# V32F20x_CM33 register map
File version: 1.0.3
CPU: CM33 r0p4, little endian, MPU, FPU, DSP, 3 interrupt priority bits, 8 SAU regions
Registers are 32-bit, read-write, reset 0x0 unless marked. A register's access mark holds for its fields unless they carry their own. Offsets are from the block's base; [hi:lo] are bit positions; {n}, {i} and the like mark numbered series; <NAME> marks a mode.

## SPI0 — SPI0 Peripheral Interface
Base 0x40010000; alternate view of UART0
Same registers: SPI{n} {0x40010000+0x800*n} (alternate view of UART{n}) (n=1..13), SEC_SPI{n} {0x50010000+0x800*n} (alternate view of SEC_UART{n}) (n=0..13)
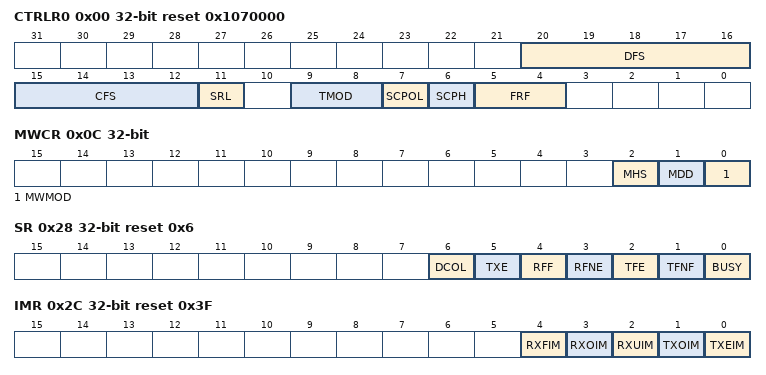
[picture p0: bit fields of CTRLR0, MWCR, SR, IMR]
0x00 CTRLR0 reset 0x1070000 — SPI Control Register 0.
  [20:16] DFS — Data Frame Size in 32-bit transfer size mode.
  [15:12] CFS — Control Frame Size.
  [11] SRL — Shift Register Loop
  [9:8] TMOD — Transfer Mode
  [7] SCPOL — Serial Clock Polarity.
  [6] SCPH — Serial Clock Phase
  [5:4] FRF — Frame Format
0x04 CTRLR1 — SPI Control Register 1.
  [15:0] NDF — Number of Data Frames
0x08 SPIEN — SPI Enable Register.
  [0] SPI_EN — SPI Enable
0x0C MWCR — SPI Microwire Control Register.
  [2] MHS — Microwire Handshaking
  [1] MDD — Microwire Control
  [0] MWMOD — Microwire Transfer Mode
0x10 SER — SPI Slave Enable Register.
  [3:0] SER — Slave Select Enable Flag
0x14 BAUDR — SPI Baud Rate Select.
  [15:0] SCKDV — SPI Clock Divider
0x18 TXFTLR — SPI Transmit FIFO Threshold Level.
  [4:0] TFT — Transmit FIFO Threshold
0x1C RXFTLR — SPI Receive FIFO Threshold Level.
  [4:0] RFT — Receive FIFO Threshold
0x20 TXFLR ro — SPI Transmit FIFO Level Register.
  [4:0] TXTFL — Transmit FIFO Level
0x24 RXFLR ro — SPI Receive FIFO Level Register.
  [4:0] RXTFL — Receive FIFO Level
0x28 SR ro reset 0x6 — SPI Status Register.
  [6] DCOL — Data Collision Error
  [5] TXE — Transmission Error
  [4] RFF — Receive FIFO Full
  [3] RFNE — Receive FIFO Not Empty
  [2] TFE — Transmit FIFO Empty
  [1] TFNF — Transmit FIFO Not Full
  [0] BUSY — SPI Busy Flag
0x2C IMR reset 0x3F — SPI Interrupt Mask Register.
  [4] RXFIM — Receive FIFO Full Interrupt Mask
  [3] RXOIM — Receive FIFO Overflow Interrupt Mask
  [2] RXUIM — Receive FIFO Underflow Interrupt Mask
  [1] TXOIM — Transmit FIFO Overflow Interrupt Mask
  [0] TXEIM — Transmit FIFO Empty Interrupt Mask
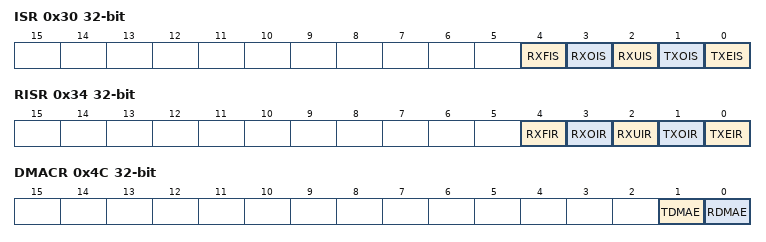
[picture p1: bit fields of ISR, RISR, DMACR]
0x30 ISR ro — SPI Interrupt Status Register.
  [4] RXFIS — Receive FIFO Full Interrupt Status
  [3] RXOIS — Receive FIFO Overflow Interrupt Status
  [2] RXUIS — Receive FIFO Underflow Interrupt Status
  [1] TXOIS — Transmit FIFO Overflow Interrupt Status
  [0] TXEIS — Transmit FIFO Empty Interrupt Status
0x34 RISR ro — SPI Raw Interrupt Status Register.
  [4] RXFIR — Receive FIFO Full Raw Interrupt Status
  [3] RXOIR — Receive FIFO Overflow Raw Interrupt Status
  [2] RXUIR — Receive FIFO Underflow Raw Interrupt Status
  [1] TXOIR — Transmit FIFO Overflow Raw Interrupt Status
  [0] TXEIR — Transmit FIFO Empty Raw Interrupt Status
0x38 TXOICR ro — SPI Transmit FIFO Overflow Interrupt Clear Registers
  [0] TXOICR — Clear Transmit FIFO Overflow Interrupt.
0x3C RXOICR ro — SPI Receive FIFO Overflow Interrupt Clear Register
  [0] RXOICR — Clear Receive FIFO Overflow Interrupt.
0x40 RXUICR ro — SPI Receive FIFO Underflow Interrupt Clear Register
  [0] RXUICR — Clear Receive FIFO Underflow Interrupt
0x4C DMACR — SPI DMA Control Register.
  [1] TDMAE — Transmit DMA Enable.
  [0] RDMAE — Receive DMA Enable.
0x50 DMATDLR — SPI DMA Transmit Data Level.
  [4:0] DMATDL — Transmit Data Level.
0x54 DMARDLR — SPI DMA Receive Data Level.
  [4:0] DMARDL — Receive Data Level.
{0x60+4i} DR{i} (i=0..35) — SPI Data Register x (for x = 0; x <= 35)
  [31:0] DR — Data Register
0xF0 RX_SAMPLE_DLY — SPI RX Sample Delay Register.
  [7:0] RSD — Rxd Sample Delay.

## ISO78160 — ISO78160 Peripheral Interface
Base 0x40040000
Same registers: ISO78161 0x40040040, ISO78162 0x41040000, ISO78163 0x41040040, SEC_ISO78160 0x50040000, SEC_ISO78161 0x50040040
0x04 BAUDDIVL — ISO78160 baud-rate low byte register.
  [7:0] BAUDDIVL — Low byte of baud-rate divider.
0x08 BAUDDIVH — ISO78160 baud-rate high byte register.
  [7:0] BAUDDIVH — High byte of baud rate divider
0x0C DATA — ISO78160 data register.
  [7:0] DATA — Read Receive data when receive data is not read by programmer and another data has been received the OVIF flag will be set
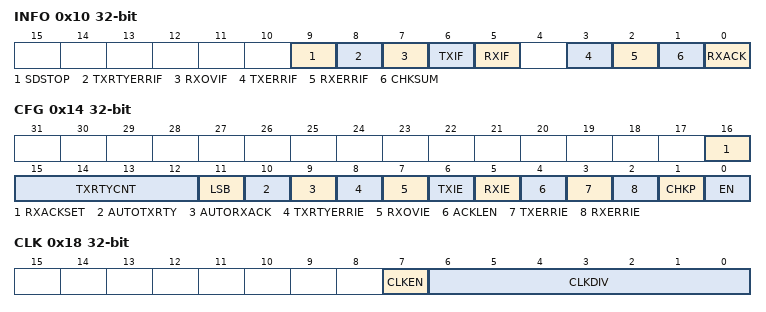
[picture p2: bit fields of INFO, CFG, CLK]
0x10 INFO ro — ISO78160 information register.
  [9] SDSTOP — Transmit finish flag.
  [8] TXRTYERRIF — Transmit Retry counter reach flag.
  [7] RXOVIF — Receive overflow flag.
  [6] TXIF — Transmit interrupt flag.
  [5] RXIF — Receive interrupt flag.
  [3] TXERRIF — When AUTOTXRTY is 0 this bit will be set to 1 when a transfer is completed and received ACK is 0
  [2] RXERRIF — When received data have check sum error this bit will be set to 1
  [1] CHKSUM — The received data s check sum bit
  [0] RXACK — The received ACK at the end of transmit
0x14 CFG — ISO78160 control register.
  [16] RXACKSET — RXACK length.
  [15:12] TXRTYCNT — Transmit retry number control register.
  [11] LSB — MSB/LSB transmit order control register.
  [10] AUTOTXRTY — Automatic transmit retry when receive ACK is 0.
  [9] AUTORXACK — Automatic response ACK as 0 when receive an error data to let transmitter re send the data
  [8] TXRTYERRIE — Transmit retry error interrupt enable register.
  [7] RXOVIE — Receive overrun interrupt enable register.
  [6] TXIE — Transmit interrupt enable register.
  [5] RXIE — Receive interrupt enable register.
  [4] ACKLEN — ACK low period when receive an error data.
  [3] TXERRIE — Transmitted data error interrupt enable register.
  [2] RXERRIE — Received data error interrupt enable register.
  [1] CHKP — Parity mode control register.
  [0] EN — ISO7816 enable register.
0x18 CLK — ISO78160 clock divider control register.
  [7] CLKEN — ISO7816 clock output enable.
  [6:0] CLKDIV — The ISO7816 clock divider ratio.
